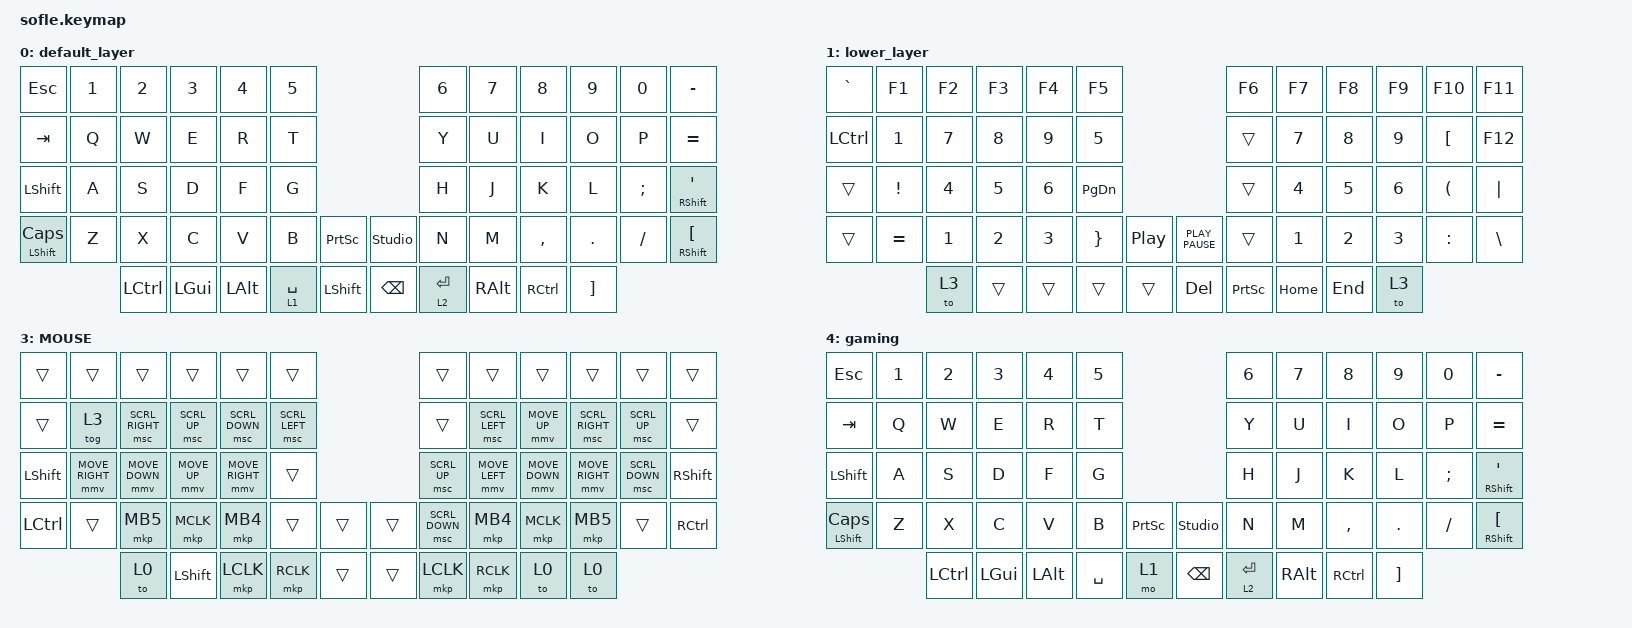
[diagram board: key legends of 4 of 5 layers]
/*
 * Copyright (c) 2020 The ZMK Contributors
 *
 * SPDX-License-Identifier: MIT
 */

#include <behaviors.dtsi>
#include <dt-bindings/zmk/bt.h>
#include <dt-bindings/zmk/keys.h>
#include <dt-bindings/zmk/pointing.h>

/ {
    behaviors {
        ht: hold_tap {
            label = "hold_tap";
            compatible = "zmk,behavior-hold-tap";
            #binding-cells = <2>;
            flavor = "tap-preferred";
            tapping-term-ms = <220>;
            quick-tap-ms = <150>;
            global-quick-tap;
            bindings = <&kp>, <&kp>;
        };

        htst: htst_small_time {
            label = "hold_tap_small_time";
            compatible = "zmk,behavior-hold-tap";
            #binding-cells = <2>;
            flavor = "tap-preferred";
            tapping-term-ms = <150>;
            quick-tap-ms = <100>;
            global-quick-tap;
            bindings = <&kp>, <&kp>;
        };

        htmo: ht_momentary {
            label = "hold_tap_momentary";
            compatible = "zmk,behavior-hold-tap";
            #binding-cells = <2>;
            flavor = "tap-preferred";
            tapping-term-ms = <200>;
            quick-tap-ms = <150>;
            global-quick-tap;
            bindings = <&mo>, <&kp>;
        };

        mmv {
            acceleration-exponent = <1>;      // 1
            time-to-max-speed-ms = <300>;    // 40
            delay-ms = <0>;                   // 0
        };

        msc {
            acceleration-exponent = <0>;      // 0
            time-to-max-speed-ms = <40>;      // 500
            delay-ms = <0>;                   // 10
        };
    };

    conditional_layers {
        compatible = "zmk,conditional-layers";

        gaming_layer {
            if-layers = <1 2>;
            then-layer = <4>;
        };
    };

    keymap {
        compatible = "zmk,keymap";

        default_layer {
            // ------------------------------------------------------------------------------------------------------------
            // |  `    |  1  |  2  |  3   |  4   |  5   |                         |  6   |  7    |  8    |  9   |   0   |       |
            // |  ESC  |  Q  |  W  |  E   |  R   |  T   |                         |  Y   |  U    |  I    |  O   |   P   | BKSPC |
            // |  TAB  |  A  |  S  |  D   |  F   |  G   |                         |  H   |  J    |  K    |  L   |   ;   |   '   |
            // | SHIFT |  Z  |  X  |  C   |  V   |  B   |  MUTE  |        | ExtPw |  N   |  M    |  ,    |  .   |   /   | SHIFT |
            //               | GUI | ALT  | CTRL | LOWER|  ENTER |        | SPACE | RAISE| CTRL  | ALT   | GUI  |

            bindings = <
&kp ESCAPE                 &kp N1  &kp N2            &kp N3        &kp N4        &kp N5                                            &kp N6         &kp N7         &kp N8     &kp N9             &kp N0    &kp MINUS
&kp TAB                    &kp Q   &kp W             &kp E         &kp R         &kp T                                             &kp Y          &kp U          &kp I      &kp O              &kp P     &kp EQUAL
&kp LEFT_SHIFT             &kp A   &kp S             &kp D         &kp F         &kp G                                             &kp H          &kp J          &kp K      &kp L              &kp SEMI  &htst RSHFT SQT
&htst LEFT_SHIFT CAPSLOCK  &kp Z   &kp X             &kp C         &kp V         &kp B          &kp PRINTSCREEN    &studio_unlock  &kp N          &kp M          &kp COMMA  &kp DOT            &kp FSLH  &htst RIGHT_SHIFT LEFT_BRACKET
                                   &kp LEFT_CONTROL  &kp LEFT_GUI  &kp LEFT_ALT  &htmo 1 SPACE  &kp LSHFT          &kp BACKSPACE   &htmo 2 ENTER  &kp RIGHT_ALT  &kp RCTRL  &kp RIGHT_BRACKET
            >;

            sensor-bindings = <&inc_dec_kp C_VOL_UP C_VOL_DN &inc_dec_kp PG_UP PG_DN>;
        };

        lower_layer {
            // TODO: Some binds are waiting for shifted keycode support.
            // ------------------------------------------------------------------------------------------------------------
            // |       |  F1 |  F2 |  F3  |  F4  |  F5  |                   |  F6  |  F7   |  F8   |  F9  |  F10  |  F11  |
            // | `     |   1 |   2 |   3  |   4  |   5  |                   |   6  |   7   |   8   |   9  |    0  |  F12  |
            // |       |  !  |  @  |  #   |  $   |  %   |                   |  ^   |  &    |  *    |  (   |   )   |   |   |
            // |       |  =  |  -  |  +   |  {   |  }   |        |  |       |  [   |  ]    |  ;    |  :   |   \   |       |
            //               |     |      |      |      |        |  |       |      |       |       |      |

            bindings = <
&kp GRAVE  &kp F1     &kp F2        &kp F3        &kp F4        &kp F5                                               &kp F6     &kp F7     &kp F8    &kp F9            &kp F10            &kp F11
&kp LCTRL  &kp N1     &kp NUMBER_7  &kp NUMBER_8  &kp NUMBER_9  &kp N5                                               &trans     &kp N7     &kp N8    &kp N9   &kp LEFT_BRACKET  &kp F12  
&trans     &kp EXCL   &kp NUMBER_4  &kp NUMBER_5  &kp NUMBER_6  &kp PAGE_DOWN                                        &trans     &kp N4     &kp N5    &kp N6   &kp LPAR          &kp PIPE 
&trans     &kp EQUAL  &kp NUMBER_1  &kp NUMBER_2  &kp NUMBER_3  &kp RBRC       &kp C_PLAY_PAUSE    &kp K_PLAY_PAUSE  &trans     &kp N1     &kp N2    &kp N3   &kp COLON         &kp BSLH   
                      &to 3         &trans        &trans        &trans         &trans              &kp DEL           &kp PSCRN  &kp HOME  &kp END  &to 3
            >;

            sensor-bindings = <&inc_dec_kp C_VOL_UP C_VOL_DN &inc_dec_kp PG_UP PG_DN>;
        };

        raise_layer {
            // ------------------------------------------------------------------------------------------------------------
            // |BTCLR| BT1  | BT2  |  BT3  |  BT4  |  BT5 |                |      |      |       |      |       |       |
            // |     | INS  | PSCR | GUI   |       |      |                | PGUP |      |   ^   |      |       |       |
            // |     | ALT  | CTRL | SHIFT |       | CAPS |                | PGDN |   <- |   v   |  ->  |  DEL  | BKSPC |
            // |     | UNDO | CUT  | COPY  | PASTE |      |      |  |      |      |      |       |      |       |       |
            //              |      |       |       |      |      |  |      |      |      |       |      |

            bindings = <
&bt BT_CLR  &bt BT_DISC 0  &bt BT_SEL 0  &bt BT_SEL 2  &bt BT_SEL 3  &bt BT_SEL 4                      &kp C_BRI_UP   &kp C_VOL_DN    &kp C_VOL_UP    &kp C_PP         &kp C_PREV  &kp C_NEXT
&kp INS     &kp PSCRN      &trans        &trans        &trans        &kp PG_UP                         &kp C_BRI_DEC  &trans          &kp UP_ARROW    &trans           &trans      &trans
&trans      &trans         &trans        &trans        &trans        &kp PG_DN                         &trans         &kp LEFT_ARROW  &kp DOWN_ARROW  &kp RIGHT_ARROW  &trans      &trans
&trans      &trans         &trans        &trans        &trans        &trans          &trans    &trans  &trans         &trans          &soft_off       &trans           &trans      &trans
                           &kp LCTRL     &to 3         &trans        &kp LEFT_SHIFT  &trans    &trans  &trans         &to 3           &to 3
            >;

            sensor-bindings = <&inc_dec_kp C_VOL_UP C_VOL_DN &inc_dec_kp PG_UP PG_DN>;
        };

        mouse {
            display-name = "MOUSE";
            bindings = <
&trans          &trans           &trans           &trans        &trans           &trans                            &trans          &trans          &trans          &trans           &trans          &trans
&trans          &tog 3           &msc SCRL_RIGHT  &msc SCRL_UP  &msc SCRL_DOWN   &msc SCRL_LEFT                    &trans          &msc SCRL_LEFT  &mmv MOVE_UP    &msc SCRL_RIGHT  &msc SCRL_UP    &trans
&kp LEFT_SHIFT  &mmv MOVE_RIGHT  &mmv MOVE_DOWN   &mmv MOVE_UP  &mmv MOVE_RIGHT  &trans                            &msc SCRL_UP    &mmv MOVE_LEFT  &mmv MOVE_DOWN  &mmv MOVE_RIGHT  &msc SCRL_DOWN  &kp RIGHT_SHIFT
&kp LCTRL       &trans           &mkp MB5         &mkp MCLK     &mkp MB4         &trans          &trans    &trans  &msc SCRL_DOWN  &mkp MB4        &mkp MCLK       &mkp MB5         &trans          &kp RCTRL
                                 &to 0            &kp LSHIFT    &mkp LCLK        &mkp RCLK       &trans    &trans  &mkp LCLK       &mkp RCLK       &to 0           &to 0
            >;
        };

        gaming {
            // ------------------------------------------------------------------------------------------------------------
            // |  `    |  1  |  2  |  3   |  4   |  5   |                         |  6   |  7    |  8    |  9   |   0   |       |
            // |  ESC  |  Q  |  W  |  E   |  R   |  T   |                         |  Y   |  U    |  I    |  O   |   P   | BKSPC |
            // |  TAB  |  A  |  S  |  D   |  F   |  G   |                         |  H   |  J    |  K    |  L   |   ;   |   '   |
            // | SHIFT |  Z  |  X  |  C   |  V   |  B   |  MUTE  |        | ExtPw |  N   |  M    |  ,    |  .   |   /   | SHIFT |
            //               | GUI | ALT  | CTRL | LOWER|  ENTER |        | SPACE | RAISE| CTRL  | ALT   | GUI  |

            bindings = <
&kp ESCAPE                 &kp N1  &kp N2            &kp N3        &kp N4        &kp N5                                        &kp N6         &kp N7         &kp N8     &kp N9             &kp N0    &kp MINUS
&kp TAB                    &kp Q   &kp W             &kp E         &kp R         &kp T                                         &kp Y          &kp U          &kp I      &kp O              &kp P     &kp EQUAL
&kp LEFT_SHIFT             &kp A   &kp S             &kp D         &kp F         &kp G                                         &kp H          &kp J          &kp K      &kp L              &kp SEMI  &htst RSHFT SQT
&htst LEFT_SHIFT CAPSLOCK  &kp Z   &kp X             &kp C         &kp V         &kp B      &kp PRINTSCREEN    &studio_unlock  &kp N          &kp M          &kp COMMA  &kp DOT            &kp FSLH  &htst RIGHT_SHIFT LEFT_BRACKET
                                   &kp LEFT_CONTROL  &kp LEFT_GUI  &kp LEFT_ALT  &kp SPACE  &mo 1              &kp BACKSPACE   &htmo 2 ENTER  &kp RIGHT_ALT  &kp RCTRL  &kp RIGHT_BRACKET
            >;

            sensor-bindings = <&inc_dec_kp C_VOL_UP C_VOL_DN &inc_dec_kp PG_UP PG_DN>;
        };
    };
};
